VERSION ""

NS_ :

BS_:

BU_: Sensor_2 Sensor_1 TPMS_ECU

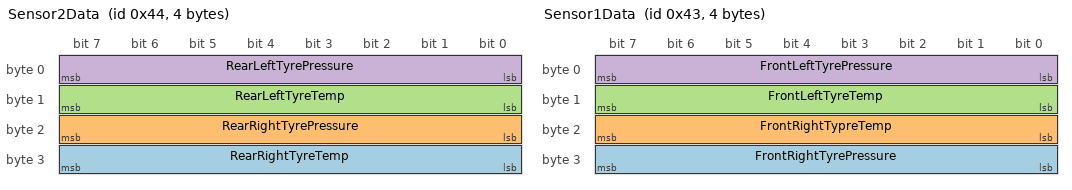
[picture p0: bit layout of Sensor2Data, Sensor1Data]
BO_ 68 Sensor2Data: 4 Sensor_2
 SG_ RearRightTyreTemp : 24|8@1- (1,0) [0|0] "" Vector__XXX
 SG_ RearRightTyrePressure : 16|8@1- (1,0) [0|0] "" Vector__XXX
 SG_ RearLeftTyreTemp : 8|8@1- (1,0) [0|0] "" Vector__XXX
 SG_ RearLeftTyrePressure : 0|8@1- (1,0) [0|0] "" Vector__XXX

BO_ 67 Sensor1Data: 4 Sensor_1
 SG_ FrontRightTyrePressure : 24|8@1- (1,0) [0|0] "" Vector__XXX
 SG_ FrontRightTypreTemp : 16|8@1- (1,0) [0|0] "" Vector__XXX
 SG_ FrontLeftTyreTemp : 8|8@1- (1,0) [0|0] "" Vector__XXX
 SG_ FrontLeftTyrePressure : 0|8@1- (1,0) [0|0] "" Vector__XXX

BA_DEF_  "BusType" STRING ;
BA_DEF_DEF_  "BusType" "CAN";
